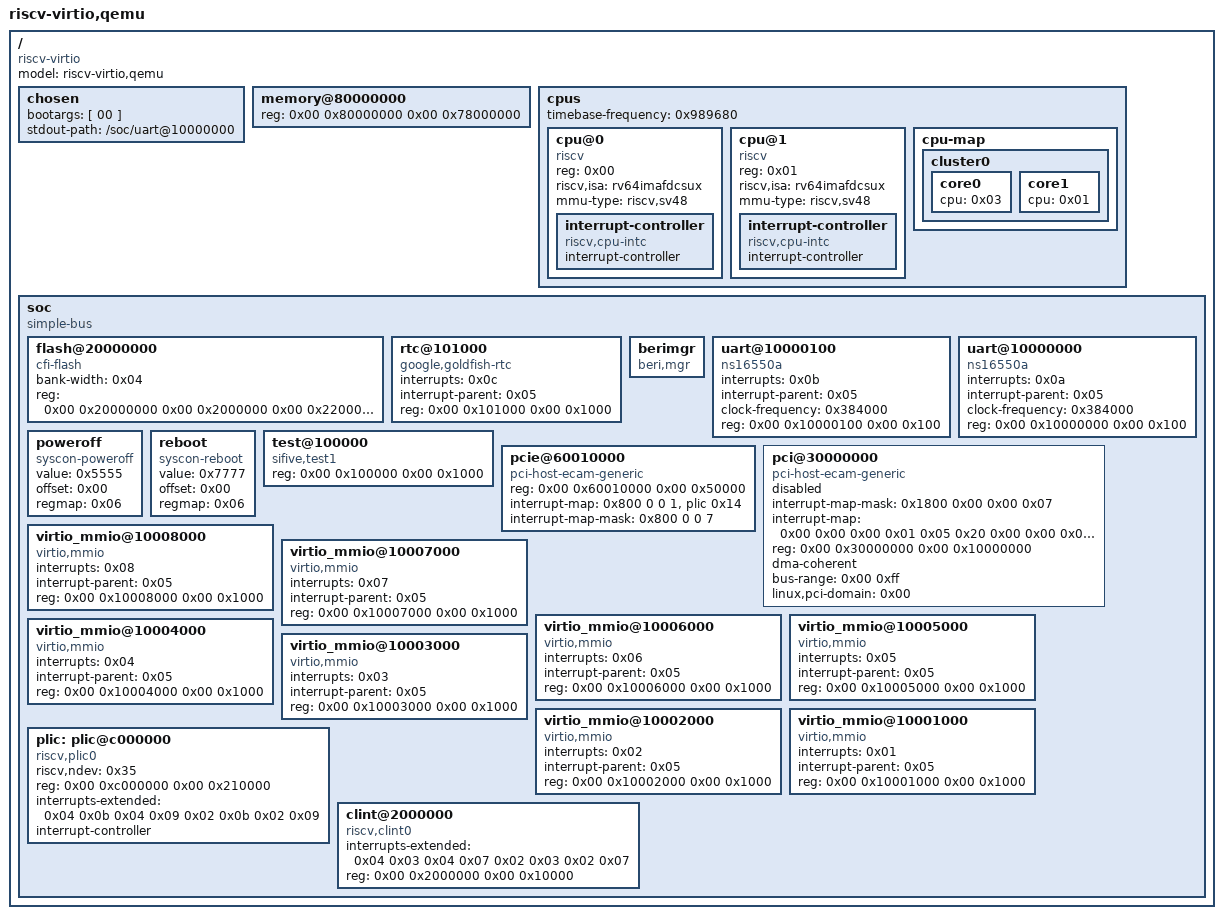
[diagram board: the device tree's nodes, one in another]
/dts-v1/;

/ {
	#address-cells = < 0x02 >;
	#size-cells = < 0x02 >;
	compatible = "riscv-virtio";
	model = "riscv-virtio,qemu";

	chosen {
		bootargs = [ 00 ];
		stdout-path = "/soc/uart@10000000";
	};

	memory@80000000 {
		device_type = "memory";
		reg = < 0x00 0x80000000 0x00 0x78000000 >;
	};

	cpus {
		#address-cells = < 0x01 >;
		#size-cells = < 0x00 >;
		timebase-frequency = < 0x989680 >;

		cpu@0 {
			phandle = < 0x03 >;
			device_type = "cpu";
			reg = < 0x00 >;
			status = "okay";
			compatible = "riscv";
			riscv,isa = "rv64imafdcsux";
			mmu-type = "riscv,sv48";

			interrupt-controller {
				#interrupt-cells = < 0x01 >;
				interrupt-controller;
				compatible = "riscv,cpu-intc";
				phandle = < 0x04 >;
			};
		};

		cpu@1 {
			phandle = < 0x01 >;
			device_type = "cpu";
			reg = < 0x01 >;
			status = "okay";
			compatible = "riscv";
			riscv,isa = "rv64imafdcsux";
			mmu-type = "riscv,sv48";

			interrupt-controller {
				#interrupt-cells = < 0x01 >;
				interrupt-controller;
				compatible = "riscv,cpu-intc";
				phandle = < 0x02 >;
			};
		};

		cpu-map {

			cluster0 {

				core0 {
					cpu = < 0x03 >;
				};

				core1 {
					cpu = < 0x01 >;
				};
			};
		};
	};

	soc {
		#address-cells = < 0x02 >;
		#size-cells = < 0x02 >;
		compatible = "simple-bus";
		ranges;

		flash@20000000 {
			bank-width = < 0x04 >;
			reg = < 0x00 0x20000000 0x00 0x2000000 0x00 0x22000000 0x00 0x2000000 >;
			compatible = "cfi-flash";
		};

		rtc@101000 {
			interrupts = < 0x0c >;
			interrupt-parent = < 0x05 >;
			reg = < 0x00 0x101000 0x00 0x1000 >;
			compatible = "google,goldfish-rtc";
		};

		berimgr {
			compatible = "beri,mgr";
		};

		uart@10000100 {
			interrupts = < 0x0b >;
			interrupt-parent = < 0x05 >;
			clock-frequency = < 0x384000 >;
			reg = < 0x00 0x10000100 0x00 0x100 >;
			compatible = "ns16550a";
		};

		uart@10000000 {
			interrupts = < 0x0a >;
			interrupt-parent = < 0x05 >;
			clock-frequency = < 0x384000 >;
			reg = < 0x00 0x10000000 0x00 0x100 >;
			compatible = "ns16550a";
		};

		poweroff {
			value = < 0x5555 >;
			offset = < 0x00 >;
			regmap = < 0x06 >;
			compatible = "syscon-poweroff";
		};

		reboot {
			value = < 0x7777 >;
			offset = < 0x00 >;
			regmap = < 0x06 >;
			compatible = "syscon-reboot";
		};

		test@100000 {
			phandle = < 0x06 >;
			reg = < 0x00 0x100000 0x00 0x1000 >;
			compatible = "sifive,test1\0sifive,test0\0syscon";
		};

		pcie@60010000 {
			compatible = "pci-host-ecam-generic";
			device_type = "pci";
			#interrupt-cells = <1>;
			#address-cells = <3>;
			#size-cells = <2>;

			reg = < 0x00 0x60010000 0x00 0x50000 >;
			reg-names = "PCI ECAM";

			//attributes      pci_addr   cpu_addr         size
			ranges =
			  <0x02000000 0 0x60050000 0 0x60050000 0 0x00010000>;	//ahci-hd bar 0

			// PCI_DEVICE(3)  INT#(1)  CONTROLLER(PHANDLE)  CONTROLLER_DATA(1)

			interrupt-map = < 0x800 0 0  1  &plic  0x14 >; 	//ahci
			interrupt-map-mask = <0x800 0 0 7>;
		};

		pci@30000000 {
			interrupt-map-mask = < 0x1800 0x00 0x00 0x07 >;
			interrupt-map = < 0x00 0x00 0x00 0x01 0x05 0x20 0x00 0x00 0x00 0x02 0x05 0x21 0x00 0x00 0x00 0x03 0x05 0x22 0x00 0x00 0x00 0x04 0x05 0x23 0x800 0x00 0x00 0x01 0x05 0x21 0x800 0x00 0x00 0x02 0x05 0x22 0x800 0x00 0x00 0x03 0x05 0x23 0x800 0x00 0x00 0x04 0x05 0x20 0x1000 0x00 0x00 0x01 0x05 0x22 0x1000 0x00 0x00 0x02 0x05 0x23 0x1000 0x00 0x00 0x03 0x05 0x20 0x1000 0x00 0x00 0x04 0x05 0x21 0x1800 0x00 0x00 0x01 0x05 0x23 0x1800 0x00 0x00 0x02 0x05 0x20 0x1800 0x00 0x00 0x03 0x05 0x21 0x1800 0x00 0x00 0x04 0x05 0x22 >;
			ranges = < 0x1000000 0x00 0x00 0x00 0x3000000 0x00 0x10000 0x2000000 0x00 0x40000000 0x00 0x40000000 0x00 0x40000000 >;
			reg = < 0x00 0x30000000 0x00 0x10000000 >;
			dma-coherent;
			bus-range = < 0x00 0xff >;
			linux,pci-domain = < 0x00 >;
			device_type = "pci";
			compatible = "pci-host-ecam-generic";
			#size-cells = < 0x02 >;
			#interrupt-cells = < 0x01 >;
			#address-cells = < 0x03 >;
			status = "disabled";
		};

		virtio_mmio@10008000 {
			interrupts = < 0x08 >;
			interrupt-parent = < 0x05 >;
			reg = < 0x00 0x10008000 0x00 0x1000 >;
			compatible = "virtio,mmio";
		};

		virtio_mmio@10007000 {
			interrupts = < 0x07 >;
			interrupt-parent = < 0x05 >;
			reg = < 0x00 0x10007000 0x00 0x1000 >;
			compatible = "virtio,mmio";
		};

		virtio_mmio@10006000 {
			interrupts = < 0x06 >;
			interrupt-parent = < 0x05 >;
			reg = < 0x00 0x10006000 0x00 0x1000 >;
			compatible = "virtio,mmio";
		};

		virtio_mmio@10005000 {
			interrupts = < 0x05 >;
			interrupt-parent = < 0x05 >;
			reg = < 0x00 0x10005000 0x00 0x1000 >;
			compatible = "virtio,mmio";
		};

		virtio_mmio@10004000 {
			interrupts = < 0x04 >;
			interrupt-parent = < 0x05 >;
			reg = < 0x00 0x10004000 0x00 0x1000 >;
			compatible = "virtio,mmio";
		};

		virtio_mmio@10003000 {
			interrupts = < 0x03 >;
			interrupt-parent = < 0x05 >;
			reg = < 0x00 0x10003000 0x00 0x1000 >;
			compatible = "virtio,mmio";
		};

		virtio_mmio@10002000 {
			interrupts = < 0x02 >;
			interrupt-parent = < 0x05 >;
			reg = < 0x00 0x10002000 0x00 0x1000 >;
			compatible = "virtio,mmio";
		};

		virtio_mmio@10001000 {
			interrupts = < 0x01 >;
			interrupt-parent = < 0x05 >;
			reg = < 0x00 0x10001000 0x00 0x1000 >;
			compatible = "virtio,mmio";
		};

		plic: plic@c000000 {
			phandle = < 0x05 >;
			riscv,ndev = < 0x35 >;
			reg = < 0x00 0xc000000 0x00 0x210000 >;
			interrupts-extended = < 0x04 0x0b 0x04 0x09 0x02 0x0b 0x02 0x09 >;
			interrupt-controller;
			compatible = "riscv,plic0";
			#interrupt-cells = < 0x01 >;
			#address-cells = < 0x00 >;
		};

		clint@2000000 {
			interrupts-extended = < 0x04 0x03 0x04 0x07 0x02 0x03 0x02 0x07 >;
			reg = < 0x00 0x2000000 0x00 0x10000 >;
			compatible = "riscv,clint0";
		};
	};
};
